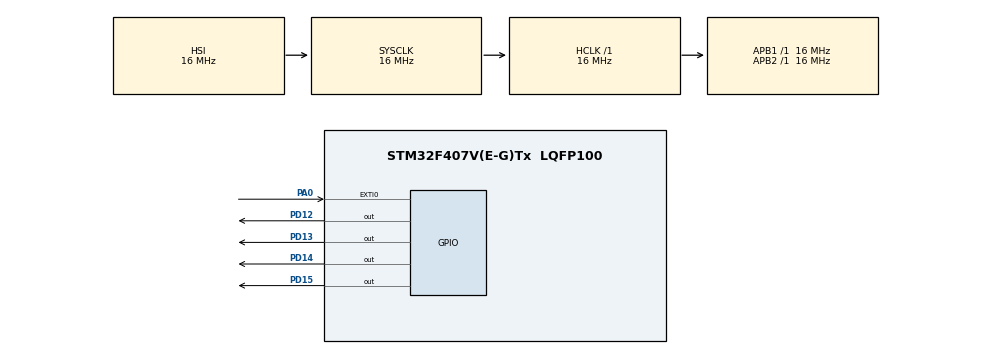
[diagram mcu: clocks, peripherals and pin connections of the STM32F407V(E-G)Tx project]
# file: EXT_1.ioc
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Mcu.Family=STM32F4
Mcu.Name=STM32F407V(E-G)Tx
Mcu.Package=LQFP100
NVIC.EXTI0_IRQn=true\:0\:0\:false\:false\:true\:true\:true
NVIC.PriorityGroup=NVIC_PRIORITYGROUP_4
PA0-WKUP.Signal=GPXTI0
PD12.Signal=GPIO_Output
PD13.Signal=GPIO_Output
PD14.Signal=GPIO_Output
PD15.Signal=GPIO_Output
ProjectManager.HeapSize=0x200
ProjectManager.StackSize=0x400
ProjectManager.TargetToolchain=STM32CubeIDE
RCC.AHBFreq_Value=16000000
RCC.APB1Freq_Value=16000000
RCC.APB2Freq_Value=16000000
RCC.CortexFreq_Value=16000000
RCC.HSE_VALUE=25000000
RCC.HSI_VALUE=16000000
RCC.LSE_VALUE=32768
RCC.SYSCLKFreq_VALUE=16000000
RCC.VCOOutputFreq_Value=192000000
board=custom

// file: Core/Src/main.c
/* USER CODE BEGIN Header */
/**
  ******************************************************************************
  * @file           : main.c
  * @brief          : Main program body
  ******************************************************************************
  * @attention
  *
  * <h2><center>&copy; Copyright (c) 2021 STMicroelectronics.
  * All rights reserved.</center></h2>
  *
  * This software component is licensed by ST under BSD 3-Clause license,
  * the "License"; You may not use this file except in compliance with the
  * License. You may obtain a copy of the License at:
  *                        opensource.org/licenses/BSD-3-Clause
  *
  ******************************************************************************
  */
/* USER CODE END Header */
#include "main.h"

void SystemClock_Config(void);
static void MX_GPIO_Init(void);

int main(void)
{

  /* MCU Configuration--------------------------------------------------------*/

  /* Reset of all peripherals, Initializes the Flash interface and the Systick. */
  HAL_Init();

  /* Configure the system clock */
  SystemClock_Config();

  /* Initialize all configured peripherals */
  MX_GPIO_Init();

  /* Infinite loop */
  while (1)
  {

    /* USER CODE BEGIN 3 */
	//LED blink at certain rate just to show that main is implemented and that
	//the ext interrupt just changes LED status
	HAL_GPIO_TogglePin(GPIOD, GPIO_PIN_13);
	HAL_Delay(500);

  }
  /* USER CODE END 3 */
}

void SystemClock_Config(void)
{
  RCC_OscInitTypeDef RCC_OscInitStruct = {0};
  RCC_ClkInitTypeDef RCC_ClkInitStruct = {0};

  /** Configure the main internal regulator output voltage
  */
  __HAL_RCC_PWR_CLK_ENABLE();
  __HAL_PWR_VOLTAGESCALING_CONFIG(PWR_REGULATOR_VOLTAGE_SCALE1);
  /** Initializes the RCC Oscillators according to the specified parameters
  * in the RCC_OscInitTypeDef structure.
  */
  RCC_OscInitStruct.OscillatorType = RCC_OSCILLATORTYPE_HSI;
  RCC_OscInitStruct.HSIState = RCC_HSI_ON;
  RCC_OscInitStruct.HSICalibrationValue = RCC_HSICALIBRATION_DEFAULT;
  RCC_OscInitStruct.PLL.PLLState = RCC_PLL_NONE;
  if (HAL_RCC_OscConfig(&RCC_OscInitStruct) != HAL_OK)
  {
    Error_Handler();
  }
  /** Initializes the CPU, AHB and APB buses clocks
  */
  RCC_ClkInitStruct.ClockType = RCC_CLOCKTYPE_HCLK|RCC_CLOCKTYPE_SYSCLK
                              |RCC_CLOCKTYPE_PCLK1|RCC_CLOCKTYPE_PCLK2;
  RCC_ClkInitStruct.SYSCLKSource = RCC_SYSCLKSOURCE_HSI;
  RCC_ClkInitStruct.AHBCLKDivider = RCC_SYSCLK_DIV1;
  RCC_ClkInitStruct.APB1CLKDivider = RCC_HCLK_DIV1;
  RCC_ClkInitStruct.APB2CLKDivider = RCC_HCLK_DIV1;

  if (HAL_RCC_ClockConfig(&RCC_ClkInitStruct, FLASH_LATENCY_0) != HAL_OK)
  {
    Error_Handler();
  }
}

static void MX_GPIO_Init(void)
{
  GPIO_InitTypeDef GPIO_InitStruct = {0};

  /* GPIO Ports Clock Enable */
  __HAL_RCC_GPIOA_CLK_ENABLE();
  __HAL_RCC_GPIOD_CLK_ENABLE();

  /*Configure GPIO pin Output Level */
  HAL_GPIO_WritePin(GPIOD, GPIO_PIN_12|GPIO_PIN_13|GPIO_PIN_14|GPIO_PIN_15, GPIO_PIN_RESET);

  /*Configure GPIO pin : PA0 */
  GPIO_InitStruct.Pin = GPIO_PIN_0;
  GPIO_InitStruct.Mode = GPIO_MODE_IT_RISING;
  GPIO_InitStruct.Pull = GPIO_NOPULL;
  HAL_GPIO_Init(GPIOA, &GPIO_InitStruct);

  /*Configure GPIO pins : PD12 PD13 PD14 PD15 */
  GPIO_InitStruct.Pin = GPIO_PIN_12|GPIO_PIN_13|GPIO_PIN_14|GPIO_PIN_15;
  GPIO_InitStruct.Mode = GPIO_MODE_OUTPUT_PP;
  GPIO_InitStruct.Pull = GPIO_NOPULL;
  GPIO_InitStruct.Speed = GPIO_SPEED_FREQ_LOW;
  HAL_GPIO_Init(GPIOD, &GPIO_InitStruct);

  /* EXTI interrupt init*/
  HAL_NVIC_SetPriority(EXTI0_IRQn, 0, 0);
  HAL_NVIC_EnableIRQ(EXTI0_IRQn);

}

/* USER CODE BEGIN 4 */
//external interrupt callback
void HAL_GPIO_EXTI_Callback(uint16_t GPIO_Pin)
{
  /* Prevent unused argument(s) compilation warning */
  UNUSED(GPIO_Pin);
  /* NOTE: This function Should not be modified, when the callback is needed,
           the HAL_GPIO_EXTI_Callback could be implemented in the user file
   */
  // code for when push button is pressed
  HAL_GPIO_TogglePin(GPIOD, GPIO_PIN_12); //toggle LED at a certain rate due to call back interrupt
  //delay to reduce the effect of switch bounce (for mechanical switch)
  for(uint32_t i=0; i<10000; i++); // few ms, wouldn't need if using ext sensor (has filter switch bouncing ripples)
  //ideally just use filter (low pass) instead of delay here

}

/* USER CODE END 4 */

void Error_Handler(void)
{
  __disable_irq();
  while (1)
  {
  }
}

/************************ (C) COPYRIGHT STMicroelectronics *****END OF FILE****/
